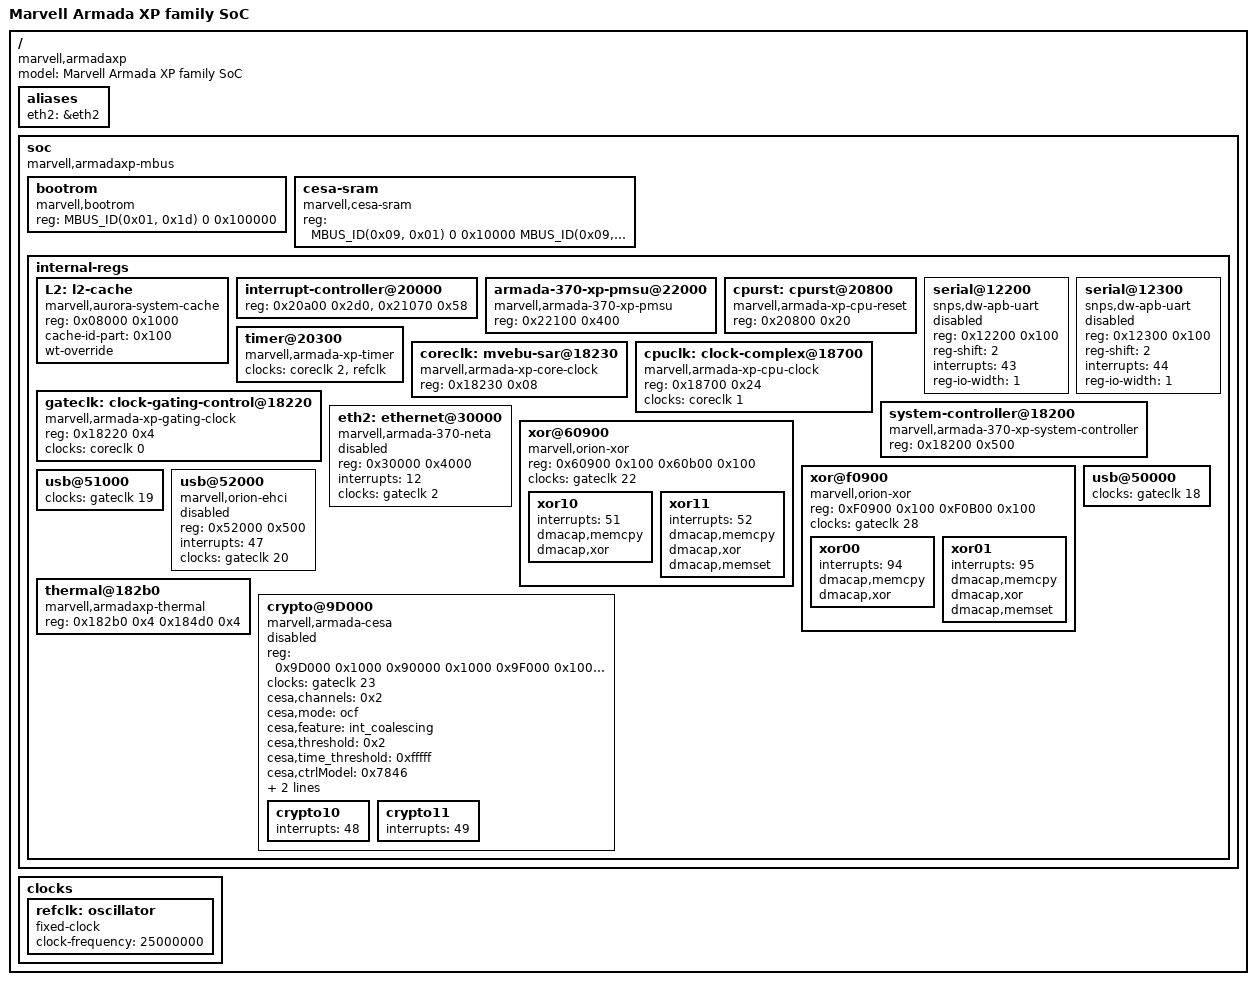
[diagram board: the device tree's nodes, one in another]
/*
 * Device Tree Include file for Marvell Armada XP family SoC
 *
 * Copyright (C) 2012 Marvell
 *
 * Lior Amsalem <alior@marvell.com>
 * Gregory CLEMENT <gregory.clement@free-electrons.com>
 * Thomas Petazzoni <thomas.petazzoni@free-electrons.com>
 * Ben Dooks <ben.dooks@codethink.co.uk>
 *
 * This file is licensed under the terms of the GNU General Public
 * License version 2.  This program is licensed "as is" without any
 * warranty of any kind, whether express or implied.
 *
 * Contains definitions specific to the Armada XP SoC that are not
 * common to all Armada SoCs.
 */

#include "armada-370-xp.dtsi"

/ {
	model = "Marvell Armada XP family SoC";
	compatible = "marvell,armadaxp", "marvell,armada-370-xp";

	aliases {
		eth2 = &eth2;
	};

	soc {
		compatible = "marvell,armadaxp-mbus", "simple-bus";

		bootrom {
			compatible = "marvell,bootrom";
			reg = <MBUS_ID(0x01, 0x1d) 0 0x100000>;
		};

		/* Security Accelerator SRAM (CESA) */
		cesa-sram {
			compatible = "marvell,cesa-sram";
			reg = <MBUS_ID(0x09, 0x01) 0 0x10000   /*chan0*/
			       MBUS_ID(0x09, 0x05) 0 0x10000>; /*chan1*/
		};

		internal-regs {
			L2: l2-cache {
				compatible = "marvell,aurora-system-cache";
				reg = <0x08000 0x1000>;
				cache-id-part = <0x100>;
				wt-override;
			};

			interrupt-controller@20000 {
			      reg = <0x20a00 0x2d0>, <0x21070 0x58>;
			};

			armada-370-xp-pmsu@22000 {
				compatible = "marvell,armada-370-xp-pmsu";
				reg = <0x22100 0x400>;
			};

			cpurst: cpurst@20800 {
				compatible = "marvell,armada-xp-cpu-reset";
				reg = <0x20800 0x20>;
				#reset-cells = <1>;
			};

			serial@12200 {
				compatible = "snps,dw-apb-uart";
				reg = <0x12200 0x100>;
				reg-shift = <2>;
				interrupts = <43>;
				reg-io-width = <1>;
				status = "disabled";
			};
			serial@12300 {
				compatible = "snps,dw-apb-uart";
				reg = <0x12300 0x100>;
				reg-shift = <2>;
				interrupts = <44>;
				reg-io-width = <1>;
				status = "disabled";
			};

			timer@20300 {
				compatible = "marvell,armada-xp-timer";
				clocks = <&coreclk 2>, <&refclk>;
				clock-names = "nbclk", "fixed";
			};

			coreclk: mvebu-sar@18230 {
				compatible = "marvell,armada-xp-core-clock";
				reg = <0x18230 0x08>;
				#clock-cells = <1>;
			};

			cpuclk: clock-complex@18700 {
				#clock-cells = <1>;
				compatible = "marvell,armada-xp-cpu-clock";
				reg = <0x18700 0x24>;
				clocks = <&coreclk 1>;
			};

			gateclk: clock-gating-control@18220 {
				compatible = "marvell,armada-xp-gating-clock";
				reg = <0x18220 0x4>;
				clocks = <&coreclk 0>;
				#clock-cells = <1>;
			};

			system-controller@18200 {
				compatible = "marvell,armada-370-xp-system-controller";
				reg = <0x18200 0x500>;
			};

			eth2: ethernet@30000 {
				compatible = "marvell,armada-370-neta";
				reg = <0x30000 0x4000>;
				interrupts = <12>;
				clocks = <&gateclk 2>;
				status = "disabled";
			};

			xor@60900 {
				compatible = "marvell,orion-xor";
				reg = <0x60900 0x100
				       0x60b00 0x100>;
				clocks = <&gateclk 22>;
				status = "okay";

				xor10 {
					interrupts = <51>;
					dmacap,memcpy;
					dmacap,xor;
				};
				xor11 {
					interrupts = <52>;
					dmacap,memcpy;
					dmacap,xor;
					dmacap,memset;
				};
			};

			xor@f0900 {
				compatible = "marvell,orion-xor";
				reg = <0xF0900 0x100
				       0xF0B00 0x100>;
				clocks = <&gateclk 28>;
				status = "okay";

				xor00 {
					interrupts = <94>;
					dmacap,memcpy;
					dmacap,xor;
				};
				xor01 {
					interrupts = <95>;
					dmacap,memcpy;
					dmacap,xor;
					dmacap,memset;
				};
			};

			usb@50000 {
				clocks = <&gateclk 18>;
			};

			usb@51000 {
				clocks = <&gateclk 19>;
			};

			usb@52000 {
				compatible = "marvell,orion-ehci";
				reg = <0x52000 0x500>;
				interrupts = <47>;
				clocks = <&gateclk 20>;
				status = "disabled";
			};

			thermal@182b0 {
				compatible = "marvell,armadaxp-thermal";
				reg = <0x182b0 0x4
					0x184d0 0x4>;
				status = "okay";
			};

			crypto@9D000 {
				compatible = "marvell,armada-cesa";
				reg = <0x9D000 0x1000	/* cesa base reg chan 0 */
				       0x90000 0x1000	/* tdma base reg chan 0 */
				       0x9F000 0x1000	/* cesa base reg chan 1 */
				       0x92000 0x1000>;	/* tdma base reg chan 1 */
				clocks = <&gateclk 23>;
				cesa,channels = <0x2>;
				cesa,mode = "ocf";	/* ocf or test */
				cesa,feature = "int_coalescing"; /* chain, int_coalescing
							   or int_per_packet */

				/* threshold and time_threshold relevant if
				   int_coalescing in use */
				cesa,threshold = <0x2>;
				cesa,time_threshold = <0xfffff>;

				cesa,ctrlModel = /bits/ 16 <0x7846>;
				cesa,ctrlRev = /bits/ 8 <2>;
				cesa,sramOffset = /bits/ 16 <0>;
				status = "disabled";

				crypto10 {
					/* channel 0 */
					interrupts = <48>;
				};
				crypto11 {
					/* channel 1 */
					interrupts = <49>;
				};
			};

		};
	};

	clocks {
		/* 25 MHz reference crystal */
		refclk: oscillator {
			compatible = "fixed-clock";
			#clock-cells = <0>;
			clock-frequency = <25000000>;
		};
	};
};
